AUTOSAR XML (schema 00047)
package /DBCImport/CANTP
  can tp config CanTpConfig_FD_CAN1: communication-cluster=FD_CAN1, can-tp-ecu=ECU1
    can tp channel CanTpChannel{0..2}: channel-id={0..2}, channel-mode=HALF-DUPLEX-MODE
    tp-connections:
      addressing-format=STANDARD, can-tp-channel=CanTpChannel1, data-pdu=NPdu_FD_CAN1_Diag_Msg_TP_Phys_Res_FD_CAN1, flow-control-pdu=NPdu_FD_CAN1_Diag_Msg_TP_Phys_Req_FD_CAN1, max-block-size=0, padding-activation=true, ta-type=PHYSICAL-CAN-FD, tp-sdu=DcmIPdu_FD_CAN1_Diag_Msg_TP_Phys_Res_FD_CAN1
      addressing-format=STANDARD, can-tp-channel=CanTpChannel1, data-pdu=NPdu_FD_CAN1_Diag_Msg_TP_Phys_Req_FD_CAN1, flow-control-pdu=NPdu_FD_CAN1_Diag_Msg_TP_Phys_Res_FD_CAN1, max-block-size=0, padding-activation=true, ta-type=PHYSICAL-CAN-FD, tp-sdu=DcmIPdu_FD_CAN1_Diag_Msg_TP_Phys_Req_FD_CAN1
      addressing-format=STANDARD, can-tp-channel=CanTpChannel0, data-pdu=NPdu_FD_CAN1_Diag_Msg_TP_Func_FD_CAN1, max-block-size=0, padding-activation=true, ta-type=FUNCTIONAL-CAN-FD, tp-sdu=DcmIPdu_FD_CAN1_Diag_Msg_TP_Func_FD_CAN1
      addressing-format=STANDARD, can-tp-channel=CanTpChannel2, data-pdu=NPdu_FD_CAN1_Normal_Msg_FD_TP_01_B, flow-control-pdu=NPdu_FD_CAN1_Normal_Msg_FD_TP_01_A, max-block-size=0, padding-activation=true, ta-type=PHYSICAL-CAN-FD, tp-sdu=ISignalIPdu_FD_CAN1_Normal_Msg_FD_TP_01_B
      addressing-format=STANDARD, can-tp-channel=CanTpChannel2, data-pdu=NPdu_FD_CAN1_Normal_Msg_FD_TP_01_A, flow-control-pdu=NPdu_FD_CAN1_Normal_Msg_FD_TP_01_B, max-block-size=0, padding-activation=true, ta-type=PHYSICAL-CAN-FD, tp-sdu=ISignalIPdu_FD_CAN1_Normal_Msg_FD_TP_01_A
    can tp node ECU1: connector=Conn_ECU1_FD_CAN1
package /DBCImport/NMCONFIG
  nm config NmConfig_FD_CAN1
    can nm cluster CanNmCluster_FD_CAN1: communication-cluster=FD_CAN1, nm-pnc-participation=true, nm-msg-cycle-time=0.1, nm-network-timeout=1.0, nm-repeat-message-time=1.2, nm-wait-bus-sleep-time=1.5
      can nm node CanNmNode_FD_CAN1: nm-node-id=2, rx-nm-pdu=[NmPdu_FD_CAN1_NM_MDPS, NmPdu_FD_CAN1_NM_ECS], tx-nm-pdu=NmPdu_FD_CAN1_NM_CGW, nm-range-config={lower-can-id=1280, upper-can-id=1407}
package /DBCImport/SWCComposition
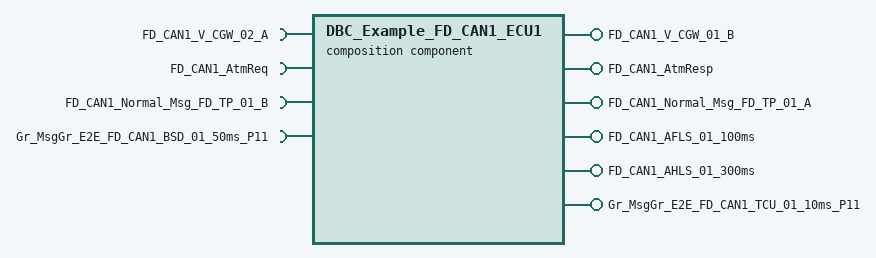
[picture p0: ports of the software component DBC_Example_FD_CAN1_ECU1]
  composition sw component type DBC_Example_FD_CAN1_ECU1
    6 x provide port:
      FD_CAN1_V_CGW_01_B: provided-interface=FD_CAN1_V_CGW_01_B
      FD_CAN1_AtmResp: provided-interface=FD_CAN1_AtmResp
      FD_CAN1_Normal_Msg_FD_TP_01_A: provided-interface=FD_CAN1_Normal_Msg_FD_TP_01_A
      FD_CAN1_AFLS_01_100ms: provided-interface=FD_CAN1_AFLS_01_100ms
      FD_CAN1_AHLS_01_300ms: provided-interface=FD_CAN1_AHLS_01_300ms
      Gr_MsgGr_E2E_FD_CAN1_TCU_01_10ms_P11: provided-interface=Gr_MsgGr_E2E_FD_CAN1_TCU_01_10ms_P11
    4 x require port:
      FD_CAN1_V_CGW_02_A: required-interface=FD_CAN1_V_CGW_02_A
      FD_CAN1_AtmReq: required-interface=FD_CAN1_AtmReq
      FD_CAN1_Normal_Msg_FD_TP_01_B: required-interface=FD_CAN1_Normal_Msg_FD_TP_01_B
      Gr_MsgGr_E2E_FD_CAN1_BSD_01_50ms_P11: required-interface=Gr_MsgGr_E2E_FD_CAN1_BSD_01_50ms_P11
package /DBCImport/CLUSTERS
  can cluster FD_CAN1: baudrate=500000, protocol-name=CAN, speed=500
    can physical channel FD_CAN1: comm-connectors=Conn_ECU1_FD_CAN1
      frame CanFrame_FD_CAN1_Diag_Msg_TP_Phys_Res_FD_CAN1: id 0x760, frame-length=8, can-addressing-mode=STANDARD, can-fd-frame-support=true
        dcm i pdu DcmIPdu_FD_CAN1_Diag_Msg_TP_Phys_Res_FD_CAN1: length=64
        n pdu NPdu_FD_CAN1_Diag_Msg_TP_Phys_Res_FD_CAN1: length=8, meta-data-length=0
      frame CanFrame_FD_CAN1_Diag_Msg_TP_Phys_Req_FD_CAN1: id 0x768, frame-length=8, can-addressing-mode=STANDARD, can-fd-frame-support=true
        dcm i pdu DcmIPdu_FD_CAN1_Diag_Msg_TP_Phys_Req_FD_CAN1: length=8
        n pdu NPdu_FD_CAN1_Diag_Msg_TP_Phys_Req_FD_CAN1: length=8, meta-data-length=0
      frame CanFrame_FD_CAN1_Diag_Msg_TP_Func_FD_CAN1: id 0x7DF, frame-length=8, can-addressing-mode=STANDARD, can-fd-frame-support=true
        dcm i pdu DcmIPdu_FD_CAN1_Diag_Msg_TP_Func_FD_CAN1: length=8
        n pdu NPdu_FD_CAN1_Diag_Msg_TP_Func_FD_CAN1: length=8, meta-data-length=0
      frame CanFrame_FD_CAN1_V_CGW_02_A: id 0x205, frame-length=8, can-addressing-mode=STANDARD, can-fd-frame-support=true
        pdu ISignalIPdu_FD_CAN1_V_CGW_02_A: length=8, minimum-delay=0.02, transmission-mode-true-timing=event-controlled-timing={number-of-repetitions=3, repetition-period=0.04}
          signal ISignal_FD_CAN1_V_CGW_02_A_V_CGW_02_A_SIG: start 0, 64 bit, opaque, init-value=8 x 0, compu {phys=raw for raw 0}, implementation-data-type=array8uint8, transfer-property=PENDING
      frame CanFrame_FD_CAN1_V_CGW_01_B: id 0x202, frame-length=8, can-addressing-mode=STANDARD, can-fd-frame-support=true
        pdu ISignalIPdu_FD_CAN1_V_CGW_01_B: length=8, minimum-delay=0.02, transmission-mode-true-timing=event-controlled-timing={number-of-repetitions=3, repetition-period=0.04}
          signal ISignal_FD_CAN1_V_CGW_01_B_V_CGW_01_B_SigGrp_1: start 0, 8 bit, little-endian, init-value=0, base-type=uint8, compu {phys=raw for raw 0..244}, transfer-property=PENDING
          signal ISignal_FD_CAN1_V_CGW_01_B_V_CGW_01_B_SigGrp_2: start 8, 4 bit, little-endian, init-value=0, base-type=uint8, compu {phys=raw for raw 0..15}, transfer-property=PENDING
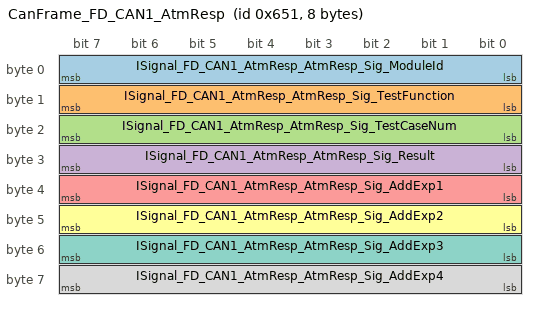
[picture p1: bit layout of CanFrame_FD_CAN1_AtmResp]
      frame CanFrame_FD_CAN1_AtmResp: id 0x651, frame-length=8, can-addressing-mode=STANDARD, can-fd-frame-support=true
        pdu ISignalIPdu_FD_CAN1_AtmResp: length=8, minimum-delay=0.02, transmission-mode-true-timing=event-controlled-timing={number-of-repetitions=3, repetition-period=0.04}
          signal ISignal_FD_CAN1_AtmResp_AtmResp_Sig_ModuleId: start 0, 8 bit, little-endian, init-value=0, base-type=uint8, compu {phys=raw for raw 0}, transfer-property=TRIGGERED
          signal ISignal_FD_CAN1_AtmResp_AtmResp_Sig_TestFunction: start 8, 8 bit, little-endian, init-value=0, base-type=uint8, compu {phys=raw for raw 0}, transfer-property=TRIGGERED
          signal ISignal_FD_CAN1_AtmResp_AtmResp_Sig_TestCaseNum: start 16, 8 bit, little-endian, init-value=0, base-type=uint8, compu {phys=raw for raw 0}, transfer-property=TRIGGERED
          signal ISignal_FD_CAN1_AtmResp_AtmResp_Sig_Result: start 24, 8 bit, little-endian, init-value=0, base-type=uint8, compu {phys=raw for raw 0}, transfer-property=TRIGGERED
          signal ISignal_FD_CAN1_AtmResp_AtmResp_Sig_AddExp1: start 32, 8 bit, little-endian, init-value=0, base-type=uint8, compu {phys=raw for raw 0}, transfer-property=TRIGGERED
          signal ISignal_FD_CAN1_AtmResp_AtmResp_Sig_AddExp2: start 40, 8 bit, little-endian, init-value=0, base-type=uint8, compu {phys=raw for raw 0}, transfer-property=TRIGGERED
          signal ISignal_FD_CAN1_AtmResp_AtmResp_Sig_AddExp3: start 48, 8 bit, little-endian, init-value=0, base-type=uint8, compu {phys=raw for raw 0}, transfer-property=TRIGGERED
          signal ISignal_FD_CAN1_AtmResp_AtmResp_Sig_AddExp4: start 56, 8 bit, little-endian, init-value=0, base-type=uint8, compu {phys=raw for raw 0}, transfer-property=TRIGGERED
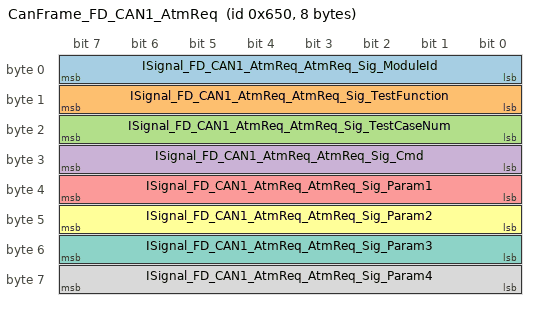
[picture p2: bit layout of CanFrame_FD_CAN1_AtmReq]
      frame CanFrame_FD_CAN1_AtmReq: id 0x650, frame-length=8, can-addressing-mode=STANDARD, can-fd-frame-support=true
        pdu ISignalIPdu_FD_CAN1_AtmReq: length=8, minimum-delay=0.02, transmission-mode-true-timing=event-controlled-timing={number-of-repetitions=3, repetition-period=0.04}
          signal ISignal_FD_CAN1_AtmReq_AtmReq_Sig_ModuleId: start 0, 8 bit, little-endian, init-value=0, base-type=uint8, compu {phys=raw for raw 0}, transfer-property=PENDING
          signal ISignal_FD_CAN1_AtmReq_AtmReq_Sig_TestFunction: start 8, 8 bit, little-endian, init-value=0, base-type=uint8, compu {phys=raw for raw 0}, transfer-property=PENDING
          signal ISignal_FD_CAN1_AtmReq_AtmReq_Sig_TestCaseNum: start 16, 8 bit, little-endian, init-value=0, base-type=uint8, compu {phys=raw for raw 0}, transfer-property=PENDING
          signal ISignal_FD_CAN1_AtmReq_AtmReq_Sig_Cmd: start 24, 8 bit, little-endian, init-value=0, base-type=uint8, compu {phys=raw for raw 0}, transfer-property=PENDING
          signal ISignal_FD_CAN1_AtmReq_AtmReq_Sig_Param1: start 32, 8 bit, little-endian, init-value=0, base-type=uint8, compu {phys=raw for raw 0}, transfer-property=PENDING
          signal ISignal_FD_CAN1_AtmReq_AtmReq_Sig_Param2: start 40, 8 bit, little-endian, init-value=0, base-type=uint8, compu {phys=raw for raw 0}, transfer-property=PENDING
          signal ISignal_FD_CAN1_AtmReq_AtmReq_Sig_Param3: start 48, 8 bit, little-endian, init-value=0, base-type=uint8, compu {phys=raw for raw 0}, transfer-property=PENDING
          signal ISignal_FD_CAN1_AtmReq_AtmReq_Sig_Param4: start 56, 8 bit, little-endian, init-value=0, base-type=uint8, compu {phys=raw for raw 0}, transfer-property=PENDING
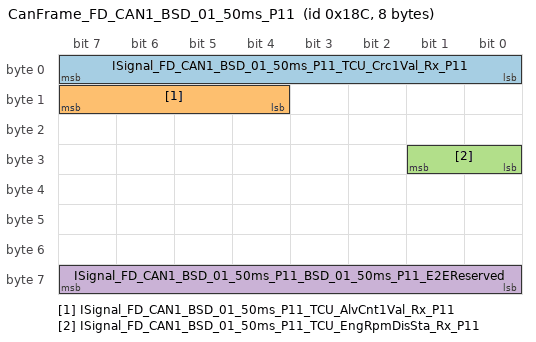
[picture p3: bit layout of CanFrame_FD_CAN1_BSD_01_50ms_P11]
      frame CanFrame_FD_CAN1_BSD_01_50ms_P11: id 0x18C, frame-length=8, can-addressing-mode=STANDARD, can-fd-frame-support=true
        pdu ISignalIPdu_FD_CAN1_BSD_01_50ms_P11: length=8, minimum-delay=0.02, transmission-mode-true-timing=cyclic-timing={time-offset=0.0, time-period=0.05}
          signal ISignal_FD_CAN1_BSD_01_50ms_P11_TCU_Crc1Val_Rx_P11: start 0, 8 bit, little-endian, init-value=0, base-type=uint8, compu {phys=raw for raw 0..255}, transfer-property=PENDING
          signal ISignal_FD_CAN1_BSD_01_50ms_P11_TCU_AlvCnt1Val_Rx_P11: start 12, 4 bit, little-endian, init-value=0, base-type=uint8, compu {phys=raw for raw 0..15}, transfer-property=PENDING
          signal ISignal_FD_CAN1_BSD_01_50ms_P11_TCU_EngRpmDisSta_Rx_P11: start 24, 2 bit, little-endian, init-value=0, base-type=uint8, compu {phys=raw for raw 0..3}, transfer-property=PENDING
          signal ISignal_FD_CAN1_BSD_01_50ms_P11_BSD_01_50ms_P11_E2EReserved: start 56, 8 bit, little-endian, init-value=0, base-type=uint8, compu {phys=0 for raw NaN}
          mapping MsgGr_FD_CAN1_BSD_01_50ms_P11: i-signal-group=MsgGr_E2E_FD_CAN1_BSD_01_50ms_P11, transfer-property=PENDING
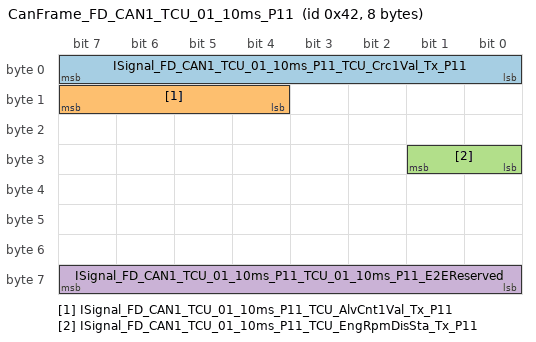
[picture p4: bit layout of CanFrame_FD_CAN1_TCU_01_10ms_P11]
      frame CanFrame_FD_CAN1_TCU_01_10ms_P11: id 0x42, frame-length=8, can-addressing-mode=STANDARD, can-fd-frame-support=true
        pdu ISignalIPdu_FD_CAN1_TCU_01_10ms_P11: length=8, minimum-delay=0.02, transmission-mode-true-timing=cyclic-timing={time-offset=0.0, time-period=0.01}
          signal ISignal_FD_CAN1_TCU_01_10ms_P11_TCU_Crc1Val_Tx_P11: start 0, 8 bit, little-endian, init-value=0, base-type=uint8, compu {phys=raw for raw 0..255}, transfer-property=PENDING
          signal ISignal_FD_CAN1_TCU_01_10ms_P11_TCU_AlvCnt1Val_Tx_P11: start 12, 4 bit, little-endian, init-value=0, base-type=uint8, compu {phys=raw for raw 0..15}, transfer-property=PENDING
          signal ISignal_FD_CAN1_TCU_01_10ms_P11_TCU_EngRpmDisSta_Tx_P11: start 24, 2 bit, little-endian, init-value=0, base-type=uint8, compu {phys=raw for raw 0..3}, transfer-property=PENDING
          signal ISignal_FD_CAN1_TCU_01_10ms_P11_TCU_01_10ms_P11_E2EReserved: start 56, 8 bit, little-endian, init-value=0, base-type=uint8, compu {phys=0 for raw NaN}
          mapping MsgGr_FD_CAN1_TCU_01_10ms_P11: i-signal-group=MsgGr_E2E_FD_CAN1_TCU_01_10ms_P11, transfer-property=PENDING
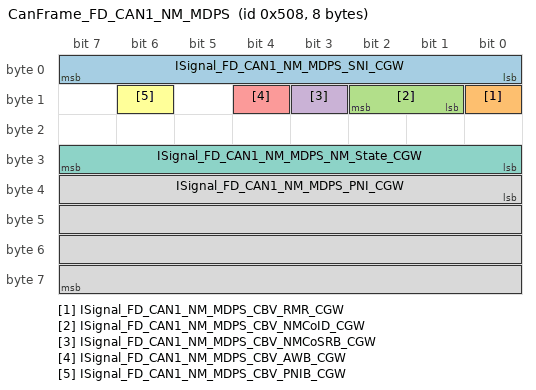
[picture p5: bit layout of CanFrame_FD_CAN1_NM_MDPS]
      frame CanFrame_FD_CAN1_NM_MDPS: id 0x508, frame-length=8, can-addressing-mode=STANDARD, can-fd-frame-support=true
        nm pdu NmPdu_FD_CAN1_NM_MDPS: length=8
          signal ISignal_FD_CAN1_NM_MDPS_SNI_CGW: start 0, 8 bit, little-endian, init-value=0, base-type=uint8, compu {phys=raw for raw 0}, transfer-property=PENDING
          signal ISignal_FD_CAN1_NM_MDPS_CBV_RMR_CGW: start 8, 1 bit, little-endian, init-value=0, base-type=boolean, compu {phys=raw for raw 0}, transfer-property=PENDING
          signal ISignal_FD_CAN1_NM_MDPS_CBV_NMCoID_CGW: start 9, 2 bit, little-endian, init-value=0, base-type=uint8, compu {phys=raw for raw 0}, transfer-property=PENDING
          signal ISignal_FD_CAN1_NM_MDPS_CBV_NMCoSRB_CGW: start 11, 1 bit, little-endian, init-value=0, base-type=boolean, compu {phys=raw for raw 0}, transfer-property=PENDING
          signal ISignal_FD_CAN1_NM_MDPS_CBV_AWB_CGW: start 12, 1 bit, little-endian, init-value=0, base-type=boolean, compu {phys=raw for raw 0}, transfer-property=PENDING
          signal ISignal_FD_CAN1_NM_MDPS_CBV_PNIB_CGW: start 14, 1 bit, little-endian, init-value=0, base-type=boolean, compu {phys=raw for raw 0}, transfer-property=PENDING
          signal ISignal_FD_CAN1_NM_MDPS_NM_State_CGW: start 24, 8 bit, little-endian, init-value=0, base-type=uint8, compu {phys=raw for raw 0}, transfer-property=PENDING
          signal ISignal_FD_CAN1_NM_MDPS_PNI_CGW: start 32, 32 bit, little-endian, init-value=0, base-type=uint32, compu {phys=raw for raw 0}, transfer-property=PENDING
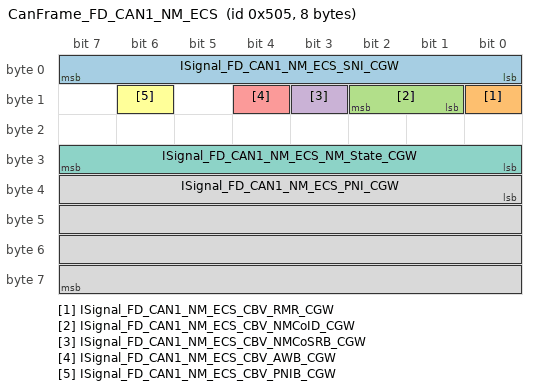
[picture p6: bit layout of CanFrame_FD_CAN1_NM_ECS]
      frame CanFrame_FD_CAN1_NM_ECS: id 0x505, frame-length=8, can-addressing-mode=STANDARD, can-fd-frame-support=true
        nm pdu NmPdu_FD_CAN1_NM_ECS: length=8
          signal ISignal_FD_CAN1_NM_ECS_SNI_CGW: start 0, 8 bit, little-endian, init-value=0, base-type=uint8, compu {phys=raw for raw 0}, transfer-property=PENDING
          signal ISignal_FD_CAN1_NM_ECS_CBV_RMR_CGW: start 8, 1 bit, little-endian, init-value=0, base-type=boolean, compu {phys=raw for raw 0}, transfer-property=PENDING
          signal ISignal_FD_CAN1_NM_ECS_CBV_NMCoID_CGW: start 9, 2 bit, little-endian, init-value=0, base-type=uint8, compu {phys=raw for raw 0}, transfer-property=PENDING
          signal ISignal_FD_CAN1_NM_ECS_CBV_NMCoSRB_CGW: start 11, 1 bit, little-endian, init-value=0, base-type=boolean, compu {phys=raw for raw 0}, transfer-property=PENDING
          signal ISignal_FD_CAN1_NM_ECS_CBV_AWB_CGW: start 12, 1 bit, little-endian, init-value=0, base-type=boolean, compu {phys=raw for raw 0}, transfer-property=PENDING
          signal ISignal_FD_CAN1_NM_ECS_CBV_PNIB_CGW: start 14, 1 bit, little-endian, init-value=0, base-type=boolean, compu {phys=raw for raw 0}, transfer-property=PENDING
          signal ISignal_FD_CAN1_NM_ECS_NM_State_CGW: start 24, 8 bit, little-endian, init-value=0, base-type=uint8, compu {phys=raw for raw 0}, transfer-property=PENDING
          signal ISignal_FD_CAN1_NM_ECS_PNI_CGW: start 32, 32 bit, little-endian, init-value=0, base-type=uint32, compu {phys=raw for raw 0}, transfer-property=PENDING
      frame CanFrame_FD_CAN1_Normal_Msg_FD_TP_01_B: id 0x75E, frame-length=64, can-addressing-mode=STANDARD, can-fd-frame-support=true
        pdu ISignalIPdu_FD_CAN1_Normal_Msg_FD_TP_01_B: length=64, minimum-delay=0.02, transmission-mode-true-timing=event-controlled-timing={number-of-repetitions=3, repetition-period=0.04}
          signal ISignal_FD_CAN1_Normal_Msg_FD_TP_01_B_FD_CAN1_Normal_Msg_FD_TP_01_B_signal: start 0, 512 bit, opaque, init-value=64 x 0, compu {phys=raw for raw 0}, implementation-data-type=array64uint8, transfer-property=PENDING
        n pdu NPdu_FD_CAN1_Normal_Msg_FD_TP_01_B: length=8, meta-data-length=0
      frame CanFrame_FD_CAN1_Normal_Msg_FD_TP_01_A: id 0x75A, frame-length=64, can-addressing-mode=STANDARD, can-fd-frame-support=true
        pdu ISignalIPdu_FD_CAN1_Normal_Msg_FD_TP_01_A: length=64, minimum-delay=0.02, transmission-mode-true-timing=event-controlled-timing={number-of-repetitions=3, repetition-period=0.04}
          signal ISignal_FD_CAN1_Normal_Msg_FD_TP_01_A_FD_CAN1_Normal_Msg_FD_TP_01_A_signal: start 0, 512 bit, opaque, init-value=64 x 0, compu {phys=raw for raw 0}, implementation-data-type=array64uint8, transfer-property=PENDING
        n pdu NPdu_FD_CAN1_Normal_Msg_FD_TP_01_A: length=64, meta-data-length=0
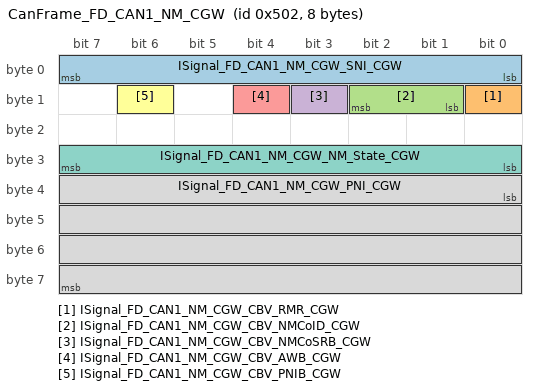
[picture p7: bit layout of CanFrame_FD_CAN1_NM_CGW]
      frame CanFrame_FD_CAN1_NM_CGW: id 0x502, frame-length=8, can-addressing-mode=STANDARD, can-fd-frame-support=true
        nm pdu NmPdu_FD_CAN1_NM_CGW: length=8
          signal ISignal_FD_CAN1_NM_CGW_SNI_CGW: start 0, 8 bit, little-endian, init-value=0, base-type=uint8, compu {phys=raw for raw 0}, transfer-property=PENDING
          signal ISignal_FD_CAN1_NM_CGW_CBV_RMR_CGW: start 8, 1 bit, little-endian, init-value=0, base-type=boolean, compu {phys=raw for raw 0}, transfer-property=PENDING
          signal ISignal_FD_CAN1_NM_CGW_CBV_NMCoID_CGW: start 9, 2 bit, little-endian, init-value=0, base-type=uint8, compu {phys=raw for raw 0}, transfer-property=PENDING
          signal ISignal_FD_CAN1_NM_CGW_CBV_NMCoSRB_CGW: start 11, 1 bit, little-endian, init-value=0, base-type=boolean, compu {phys=raw for raw 0}, transfer-property=PENDING
          signal ISignal_FD_CAN1_NM_CGW_CBV_AWB_CGW: start 12, 1 bit, little-endian, init-value=0, base-type=boolean, compu {phys=raw for raw 0}, transfer-property=PENDING
          signal ISignal_FD_CAN1_NM_CGW_CBV_PNIB_CGW: start 14, 1 bit, little-endian, init-value=0, base-type=boolean, compu {phys=raw for raw 0}, transfer-property=PENDING
          signal ISignal_FD_CAN1_NM_CGW_NM_State_CGW: start 24, 8 bit, little-endian, init-value=0, base-type=uint8, compu {phys=raw for raw 0}, transfer-property=PENDING
          signal ISignal_FD_CAN1_NM_CGW_PNI_CGW: start 32, 32 bit, little-endian, init-value=0, base-type=uint32, compu {phys=raw for raw 0}, transfer-property=PENDING
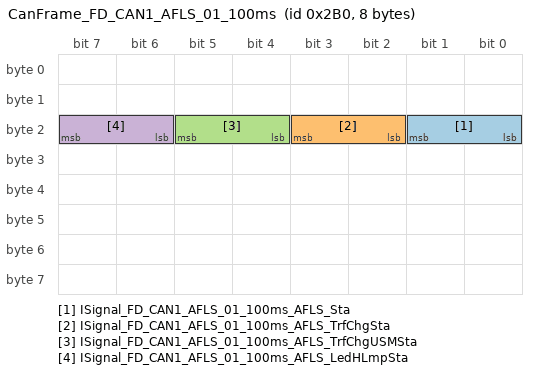
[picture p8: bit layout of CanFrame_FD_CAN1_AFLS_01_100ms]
      frame CanFrame_FD_CAN1_AFLS_01_100ms: id 0x2B0, frame-length=8, can-addressing-mode=STANDARD, can-fd-frame-support=true
        pdu ISignalIPdu_FD_CAN1_AFLS_01_100ms: length=8, minimum-delay=0.02, transmission-mode-true-timing=cyclic-timing={time-offset=0.0, time-period=0.1}
          signal ISignal_FD_CAN1_AFLS_01_100ms_AFLS_Sta: start 16, 2 bit, little-endian, init-value=0, base-type=uint8, compu {phys=raw for raw 0}, transfer-property=PENDING
          signal ISignal_FD_CAN1_AFLS_01_100ms_AFLS_TrfChgSta: start 18, 2 bit, little-endian, init-value=0, base-type=uint8, compu {phys=raw for raw 0}, transfer-property=PENDING
          signal ISignal_FD_CAN1_AFLS_01_100ms_AFLS_TrfChgUSMSta: start 20, 2 bit, little-endian, init-value=0, base-type=uint8, compu {phys=raw for raw 0}, transfer-property=PENDING
          signal ISignal_FD_CAN1_AFLS_01_100ms_AFLS_LedHLmpSta: start 22, 2 bit, little-endian, init-value=0, base-type=uint8, compu {phys=raw for raw 0}, transfer-property=PENDING
      frame CanFrame_FD_CAN1_AHLS_01_300ms: id 0x400, frame-length=8, can-addressing-mode=STANDARD, can-fd-frame-support=true
        pdu ISignalIPdu_FD_CAN1_AHLS_01_300ms: length=8, minimum-delay=0.02, transmission-mode-true-timing=cyclic-timing={time-offset=0.0, time-period=0.3}
          signal ISignal_FD_CAN1_AHLS_01_300ms_AHLS_WrnLmpDis: start 0, 2 bit, little-endian, init-value=0, base-type=uint8, compu {phys=raw for raw 0}, transfer-property=PENDING
          signal ISignal_FD_CAN1_AHLS_01_300ms_AHLS_WrnMsgDis: start 2, 2 bit, little-endian, init-value=0, base-type=uint8, compu {phys=raw for raw 0}, transfer-property=PENDING
package /DBCImport/IPDUGROUPS
  i signal i pdu group ISignalIPduGroupRx_ECU1_FD_CAN1_PNC32: communication-direction=IN, communication-mode=rx
    i-signal-i-pdus:
      ISignalIPdu_FD_CAN1_V_CGW_02_A
      ISignalIPdu_FD_CAN1_AtmReq
      ISignalIPdu_FD_CAN1_BSD_01_50ms_P11
      ISignalIPdu_FD_CAN1_Normal_Msg_FD_TP_01_B
  i signal i pdu group ISignalIPduGroupTx_ECU1_FD_CAN1_PNC32: communication-direction=OUT, communication-mode=tx
    i-signal-i-pdus:
      ISignalIPdu_FD_CAN1_V_CGW_01_B
      ISignalIPdu_FD_CAN1_AtmResp
      ISignalIPdu_FD_CAN1_TCU_01_10ms_P11
      ISignalIPdu_FD_CAN1_Normal_Msg_FD_TP_01_A
      ISignalIPdu_FD_CAN1_AFLS_01_100ms
      ISignalIPdu_FD_CAN1_AHLS_01_300ms
package /DBCImport/INTERFACES
  10 x sender receiver interface:
    FD_CAN1_AFLS_01_100ms
      4 x data, all with base-type=uint8, compu {phys=raw for raw 0}, type=AUTOSAR_uint8, init-value=0:
        AFLS_Sta
        AFLS_TrfChgSta
        AFLS_TrfChgUSMSta
        AFLS_LedHLmpSta
    FD_CAN1_AHLS_01_300ms
      data AHLS_WrnLmpDis: base-type=uint8, compu {phys=raw for raw 0}, type=AUTOSAR_uint8, init-value=0
      data AHLS_WrnMsgDis: base-type=uint8, compu {phys=raw for raw 0}, type=AUTOSAR_uint8, init-value=0
    FD_CAN1_AtmReq
      8 x data, all with base-type=uint8, compu {phys=raw for raw 0}, type=AUTOSAR_uint8, init-value=0:
        AtmReq_Sig_Param4
        AtmReq_Sig_Param3
        AtmReq_Sig_Param2
        AtmReq_Sig_Param1
        AtmReq_Sig_Cmd
        AtmReq_Sig_TestCaseNum
        AtmReq_Sig_TestFunction
        AtmReq_Sig_ModuleId
    FD_CAN1_AtmResp
      8 x data, all with base-type=uint8, compu {phys=raw for raw 0}, type=AUTOSAR_uint8, init-value=0:
        AtmResp_Sig_AddExp4
        AtmResp_Sig_AddExp3
        AtmResp_Sig_AddExp2
        AtmResp_Sig_AddExp1
        AtmResp_Sig_Result
        AtmResp_Sig_TestCaseNum
        AtmResp_Sig_TestFunction
        AtmResp_Sig_ModuleId
    FD_CAN1_Normal_Msg_FD_TP_01_A
      data FD_CAN1_Normal_Msg_FD_TP_01_A_signal: compu {phys=raw for raw 0}, sw-impl-policy=QUEUED, type=array64uint8
    FD_CAN1_Normal_Msg_FD_TP_01_B
      data FD_CAN1_Normal_Msg_FD_TP_01_B_signal: compu {phys=raw for raw 0}, sw-impl-policy=QUEUED, type=array64uint8
    FD_CAN1_V_CGW_01_B
      data V_CGW_01_B_SigGrp_2: base-type=uint8, compu {phys=raw for raw 0..15}, type=AUTOSAR_uint8, init-value=0
      data V_CGW_01_B_SigGrp_1: base-type=uint8, compu {phys=raw for raw 0..244}, type=AUTOSAR_uint8, init-value=0
    FD_CAN1_V_CGW_02_A
      data V_CGW_02_A_SIG: compu {phys=raw for raw 0}, type=array8uint8, init-value=8 x 0
    Gr_MsgGr_E2E_FD_CAN1_BSD_01_50ms_P11
      data MsgGr_E2E_FD_CAN1_BSD_01_50ms_P11: type=MsgGr_E2E_FD_CAN1_BSD_01_50ms_P11, init-value=fields=[0, 0]
    Gr_MsgGr_E2E_FD_CAN1_TCU_01_10ms_P11
      data MsgGr_E2E_FD_CAN1_TCU_01_10ms_P11: type=MsgGr_E2E_FD_CAN1_TCU_01_10ms_P11, init-value=fields=[0, 0]
package /DBCImport/ISIGNALGROUPS
  i signal group MsgGr_E2E_FD_CAN1_BSD_01_50ms_P11:
    com-based-signal-group-transformations=XfRx_FD_CAN1_P11_8
    i-signal=[ISignal_FD_CAN1_BSD_01_50ms_P11_TCU_Crc1Val_Rx_P11, ISignal_FD_CAN1_BSD_01_50ms_P11_TCU_AlvCnt1Val_Rx_P11, ISignal_FD_CAN1_BSD_01_50ms_P11_TCU_EngRpmDisSta_Rx_P11, ISignal_FD_CAN1_BSD_01_50ms_P11_BSD_01_50ms_P11_E2EReserved]
    system-signal-group=MsgGr_E2E_FD_CAN1_BSD_01_50ms_P11
    end-to-end-transformation-i-signal-props{transformer=XfTechRx_E2EXf_P11_8, data-ids=63884, data-length=64}
  i signal group MsgGr_E2E_FD_CAN1_TCU_01_10ms_P11:
    com-based-signal-group-transformations=XfTx_FD_CAN1_P11_8
    i-signal=[ISignal_FD_CAN1_TCU_01_10ms_P11_TCU_Crc1Val_Tx_P11, ISignal_FD_CAN1_TCU_01_10ms_P11_TCU_AlvCnt1Val_Tx_P11, ISignal_FD_CAN1_TCU_01_10ms_P11_TCU_EngRpmDisSta_Tx_P11, ISignal_FD_CAN1_TCU_01_10ms_P11_TCU_01_10ms_P11_E2EReserved]
    system-signal-group=MsgGr_E2E_FD_CAN1_TCU_01_10ms_P11
    end-to-end-transformation-i-signal-props{transformer=XfTechTx_E2EXf_P11_8, data-ids=63554, data-length=64}
package /DBCImport/ImplementationDataTypes_FD_CAN1
  4 x impl type:
    MsgGr_E2E_FD_CAN1_BSD_01_50ms_P11: category=STRUCTURE
      element TCU_EngRpmDisSta_Rx_P11: implementation-data-type=uint8
      element BSD_01_50ms_P11_E2EReserved: implementation-data-type=uint8
    MsgGr_E2E_FD_CAN1_TCU_01_10ms_P11: category=STRUCTURE
      element TCU_EngRpmDisSta_Tx_P11: implementation-data-type=uint8
      element TCU_01_10ms_P11_E2EReserved: implementation-data-type=uint8
    array64uint8: category=ARRAY
      element uint8: array-size=64, array-size-semantics=FIXED-SIZE, implementation-data-type=uint8
    array8uint8: category=ARRAY
      element uint8: array-size=8, array-size-semantics=FIXED-SIZE, implementation-data-type=uint8
